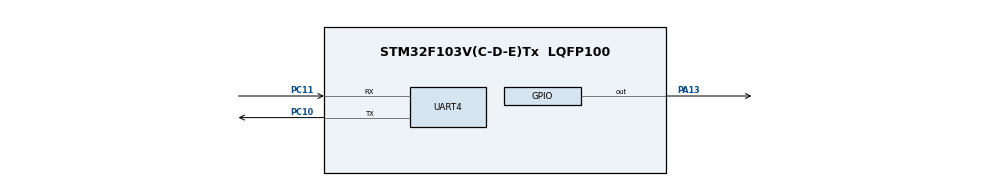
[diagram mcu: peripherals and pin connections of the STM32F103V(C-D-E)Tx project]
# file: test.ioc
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FREERTOS.Tasks01=defaultTask,24,128,StartDefaultTask,Default,NULL,Dynamic,NULL,NULL
Mcu.Family=STM32F1
Mcu.Name=STM32F103V(C-D-E)Tx
Mcu.Package=LQFP100
NVIC.PriorityGroup=NVIC_PRIORITYGROUP_4
PA13.Signal=GPIO_Output
PC10.Mode=Multiprocessor_communication
PC10.Signal=UART4_TX
PC11.Mode=Multiprocessor_communication
PC11.Signal=UART4_RX
ProjectManager.HeapSize=0x200
ProjectManager.StackSize=0x400
ProjectManager.TargetToolchain=MDK-ARM V5
RCC.APB1Freq_Value=8000000
RCC.APB2Freq_Value=8000000
UART4.VirtualMode=Asynchronous
VP_FREERTOS_VS_CMSIS_V2.Mode=CMSIS_V2
VP_SYS_VS_ND.Mode=No_Debug
board=custom

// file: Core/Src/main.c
/* USER CODE BEGIN Header */
/**
  ******************************************************************************
  * @file           : main.c
  * @brief          : Main program body
  ******************************************************************************
  * @attention
  *
  * Copyright (c) 2023 STMicroelectronics.
  * All rights reserved.
  *
  * This software is licensed under terms that can be found in the LICENSE file
  * in the root directory of this software component.
  * If no LICENSE file comes with this software, it is provided AS-IS.
  *
  ******************************************************************************
  */
/* USER CODE END Header */
#include "main.h"
#include "cmsis_os.h"

/* USER CODE BEGIN Includes */
#include "stdio.h"
/* USER CODE END Includes */

UART_HandleTypeDef huart4;

/* Definitions for defaultTask */
osThreadId_t defaultTaskHandle;
const osThreadAttr_t defaultTask_attributes = {
  .name = "defaultTask",
  .stack_size = 128 * 4,
  .priority = (osPriority_t) osPriorityNormal,
};
/* USER CODE BEGIN PV */
uint16_t num=0;
/* USER CODE END PV */

void SystemClock_Config(void);
static void MX_GPIO_Init(void);
static void MX_UART4_Init(void);
void StartDefaultTask(void *argument);

int main(void)
{

  /* MCU Configuration--------------------------------------------------------*/

  /* Reset of all peripherals, Initializes the Flash interface and the Systick. */
  HAL_Init();

  /* Configure the system clock */
  SystemClock_Config();

  /* Initialize all configured peripherals */
  MX_GPIO_Init();
  MX_UART4_Init();

  /* Init scheduler */
  osKernelInitialize();

  /* Create the thread(s) */
  /* creation of defaultTask */
  defaultTaskHandle = osThreadNew(StartDefaultTask, NULL, &defaultTask_attributes);

  /* Start scheduler */
  osKernelStart();

  /* We should never get here as control is now taken by the scheduler */
  /* Infinite loop */
  while (1)
  {

    /* USER CODE BEGIN 3 */
		HAL_Delay(1000);
		num++;
		HAL_GPIO_WritePin(GPIOA, GPIO_PIN_13, GPIO_PIN_RESET);
		HAL_Delay(1000);
		HAL_GPIO_WritePin(GPIOA, GPIO_PIN_13, GPIO_PIN_SET);
  }
  /* USER CODE END 3 */
}

void SystemClock_Config(void)
{
  RCC_OscInitTypeDef RCC_OscInitStruct = {0};
  RCC_ClkInitTypeDef RCC_ClkInitStruct = {0};

  /** Initializes the RCC Oscillators according to the specified parameters
  * in the RCC_OscInitTypeDef structure.
  */
  RCC_OscInitStruct.OscillatorType = RCC_OSCILLATORTYPE_HSI;
  RCC_OscInitStruct.HSIState = RCC_HSI_ON;
  RCC_OscInitStruct.HSICalibrationValue = RCC_HSICALIBRATION_DEFAULT;
  RCC_OscInitStruct.PLL.PLLState = RCC_PLL_NONE;
  if (HAL_RCC_OscConfig(&RCC_OscInitStruct) != HAL_OK)
  {
    Error_Handler();
  }

  /** Initializes the CPU, AHB and APB buses clocks
  */
  RCC_ClkInitStruct.ClockType = RCC_CLOCKTYPE_HCLK|RCC_CLOCKTYPE_SYSCLK
                              |RCC_CLOCKTYPE_PCLK1|RCC_CLOCKTYPE_PCLK2;
  RCC_ClkInitStruct.SYSCLKSource = RCC_SYSCLKSOURCE_HSI;
  RCC_ClkInitStruct.AHBCLKDivider = RCC_SYSCLK_DIV1;
  RCC_ClkInitStruct.APB1CLKDivider = RCC_HCLK_DIV1;
  RCC_ClkInitStruct.APB2CLKDivider = RCC_HCLK_DIV1;

  if (HAL_RCC_ClockConfig(&RCC_ClkInitStruct, FLASH_LATENCY_0) != HAL_OK)
  {
    Error_Handler();
  }
}

static void MX_UART4_Init(void)
{

  huart4.Instance = UART4;
  huart4.Init.BaudRate = 115200;
  huart4.Init.WordLength = UART_WORDLENGTH_8B;
  huart4.Init.StopBits = UART_STOPBITS_1;
  huart4.Init.Parity = UART_PARITY_NONE;
  huart4.Init.Mode = UART_MODE_TX_RX;
  huart4.Init.HwFlowCtl = UART_HWCONTROL_NONE;
  huart4.Init.OverSampling = UART_OVERSAMPLING_16;
  if (HAL_MultiProcessor_Init(&huart4, 0, UART_WAKEUPMETHOD_IDLELINE) != HAL_OK)
  {
    Error_Handler();
  }

}

static void MX_GPIO_Init(void)
{
  GPIO_InitTypeDef GPIO_InitStruct = {0};

  /* GPIO Ports Clock Enable */
  __HAL_RCC_GPIOA_CLK_ENABLE();
  __HAL_RCC_GPIOC_CLK_ENABLE();

  /*Configure GPIO pin Output Level */
  HAL_GPIO_WritePin(GPIOA, GPIO_PIN_13, GPIO_PIN_RESET);

  /*Configure GPIO pin : PA13 */
  GPIO_InitStruct.Pin = GPIO_PIN_13;
  GPIO_InitStruct.Mode = GPIO_MODE_OUTPUT_PP;
  GPIO_InitStruct.Pull = GPIO_NOPULL;
  GPIO_InitStruct.Speed = GPIO_SPEED_FREQ_LOW;
  HAL_GPIO_Init(GPIOA, &GPIO_InitStruct);

}

/* USER CODE BEGIN 4 */
//重定向print
int fputc(int ch, FILE *f)//printf
{
	HAL_UART_Transmit(&huart4, (uint8_t *)&ch, 1,0xffff);  //发送一个字节的数据到你希望的串口
	return (ch);
}

/* USER CODE END 4 */

void StartDefaultTask(void *argument)
{
  for(;;)
  {
    osDelay(1);
  }
}

void Error_Handler(void)
{
  __disable_irq();
  while (1)
  {
  }
}
